VERSION ""

NS_ :

BS_:

BU_: VCU BMS MCU DISPLAY

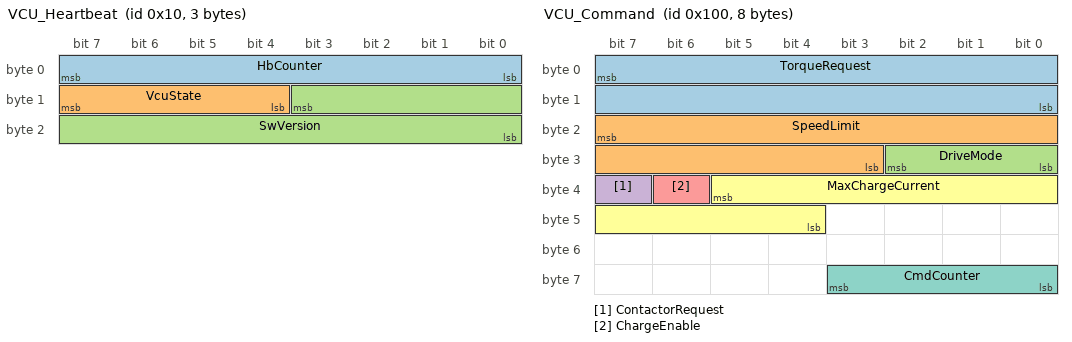
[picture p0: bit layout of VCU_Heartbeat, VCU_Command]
BO_ 16 VCU_Heartbeat: 3 VCU
 SG_ HbCounter : 7|8@0+ (1,0) [0|255] "" MCU,BMS,DISPLAY
 SG_ VcuState : 15|4@0+ (1,0) [0|9] "" MCU,BMS,DISPLAY
 SG_ SwVersion : 11|12@0+ (1,0) [0|4095] "" DISPLAY

BO_ 256 VCU_Command: 8 VCU
 SG_ TorqueRequest : 7|16@0+ (0.1,-1000) [-1000|1000] "Nm" MCU
 SG_ SpeedLimit : 23|13@0+ (1,0) [500|8000] "rpm" MCU
 SG_ DriveMode : 26|3@0+ (1,0) [0|4] "" MCU,BMS,DISPLAY
 SG_ ContactorRequest : 39|1@0+ (1,0) [0|1] "" BMS
 SG_ ChargeEnable : 38|1@0+ (1,0) [0|1] "" BMS
 SG_ MaxChargeCurrent : 37|10@0+ (0.5,0) [0|500] "A" BMS
 SG_ CmdCounter : 59|4@0+ (1,0) [0|0] "" MCU,BMS

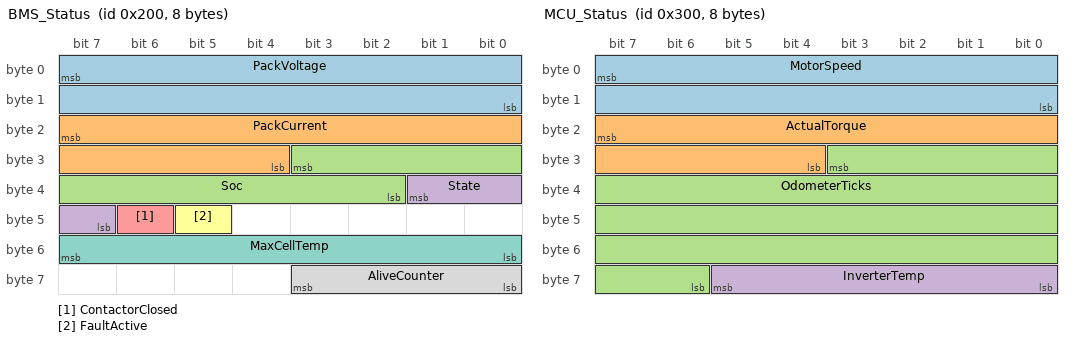
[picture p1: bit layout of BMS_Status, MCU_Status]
BO_ 512 BMS_Status: 8 BMS
 SG_ PackVoltage : 7|16@0+ (0.1,0) [0|6553.5] "V" VCU,DISPLAY
 SG_ PackCurrent : 23|12@0+ (0.1,-200) [-200|200] "A" VCU,DISPLAY
 SG_ Soc : 27|10@0+ (0.1,0) [0|100] "%" VCU,DISPLAY
 SG_ State : 33|3@0+ (1,0) [0|5] "" VCU,DISPLAY
 SG_ ContactorClosed : 46|1@0+ (1,0) [0|1] "" VCU
 SG_ FaultActive : 45|1@0+ (1,0) [0|1] "" VCU,DISPLAY
 SG_ MaxCellTemp : 55|8@0+ (1,-40) [-40|215] "degC" VCU,DISPLAY
 SG_ AliveCounter : 59|4@0+ (1,0) [0|15] "" VCU

BO_ 768 MCU_Status: 8 MCU
 SG_ MotorSpeed : 7|16@0+ (0.5,-10000) [-10000|10000] "rpm" VCU,DISPLAY
 SG_ ActualTorque : 23|12@0+ (0.5,-1000) [-1000|1000] "Nm" VCU
 SG_ OdometerTicks : 27|30@0+ (1,0) [0|0] "" VCU,DISPLAY
 SG_ InverterTemp : 61|6@0+ (2,-40) [-40|86] "degC" VCU,DISPLAY

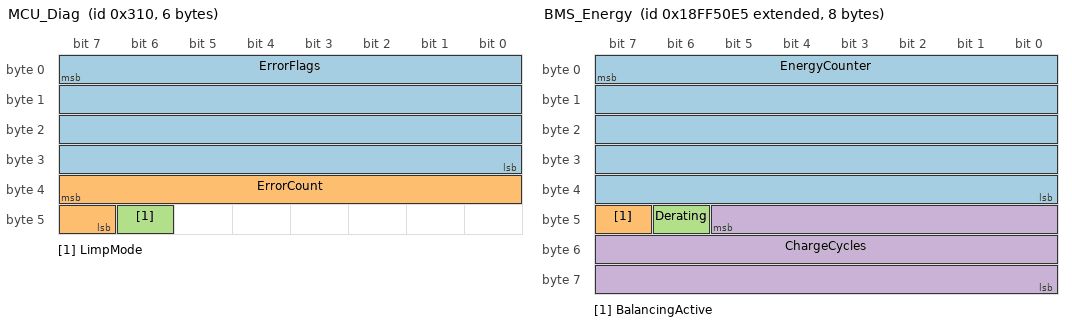
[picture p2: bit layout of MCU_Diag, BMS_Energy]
BO_ 784 MCU_Diag: 6 MCU
 SG_ ErrorFlags : 7|32@0+ (1,0) [0|4294967295] "" VCU,DISPLAY
 SG_ ErrorCount : 39|9@0+ (1,0) [0|511] "" VCU
 SG_ LimpMode : 46|1@0+ (1,0) [0|1] "" VCU,DISPLAY

BO_ 2566869221 BMS_Energy: 8 BMS
 SG_ EnergyCounter : 7|40@0+ (1,0) [0|0] "Wh" VCU,DISPLAY
 SG_ BalancingActive : 47|1@0+ (1,0) [0|1] "" VCU
 SG_ Derating : 46|1@0+ (1,0) [0|1] "" VCU,DISPLAY
 SG_ ChargeCycles : 45|22@0+ (1,0) [0|4000000] "" VCU

CM_ "Example vehicle network.
All signals are Motorola (big-endian) and unsigned.";
CM_ BO_ 512 "Battery pack status";
CM_ SG_ 512 Soc "State of charge";

BA_DEF_ BO_ "GenMsgCycleTime" INT 0 65535;
BA_DEF_DEF_ "GenMsgCycleTime" 0;
BA_ "GenMsgCycleTime" BO_ 16 50;
BA_ "GenMsgCycleTime" BO_ 256 10;
BA_ "GenMsgCycleTime" BO_ 512 100;
BA_ "GenMsgCycleTime" BO_ 768 20;
BA_ "GenMsgCycleTime" BO_ 2566869221 1000;

VAL_ 256 DriveMode 0 "Park" 1 "Reverse" 2 "Neutral" 3 "Drive" 4 "Sport" ;
VAL_ 512 State 0 "Init" 1 "Standby" 2 "Drive" 3 "Charge" 4 "Fault" 5 "Shutdown" ;
